# PIC32MZ2048EFM144 register map
Vendor: Microchip
Registers are 32-bit, read-write, reset 0x0 unless marked. A register's access mark holds for its fields unless they carry their own. Addresses are absolute, and some are shared; only a register's first bit layout is shown; [hi:lo] are bit positions; {n}, {i} and the like mark numbered series.

## INT
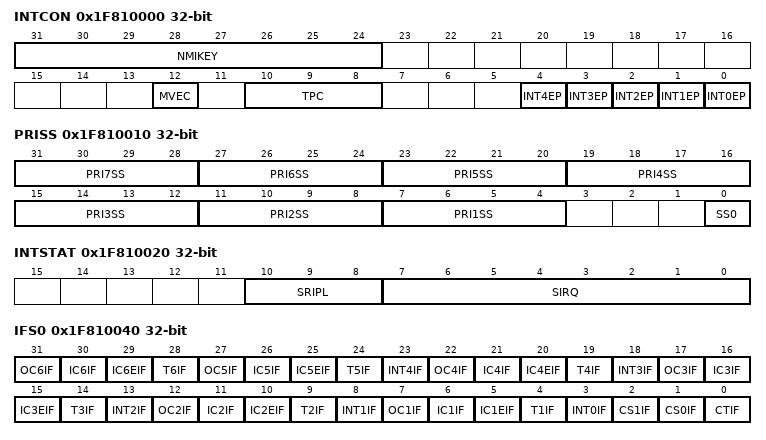
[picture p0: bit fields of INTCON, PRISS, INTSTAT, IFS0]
0x1F810000 INTCON reset not defined — (power-on value xxxxxxxx---------x-0-000---00000)
  [31:24] NMIKEY wo, [12] MVEC, [10:8] TPC, [n] INT{n}EP (n=0..4)
0x1F810010 PRISS
  [4n+3:4n] PRI{n}SS (n=1..7), [0] SS0
0x1F810020 INTSTAT ro
  [10:8] SRIPL, [7:0] SIRQ
0x1F810030 IPTMR
0x1F810040 IFS0
  [31] OC6IF, [30] IC6IF, [29] IC6EIF, [28] T6IF, [5n+2] OC{n}IF (n=1..5), [5n+1] IC{n}IF (n=1..5), [5n] IC{n}EIF (n=1..5), [5n-1] T{n}IF (n=1..5), [5n+3] INT{n}IF (n=0..4), [2] CS1IF, [1] CS0IF, [0] CTIF
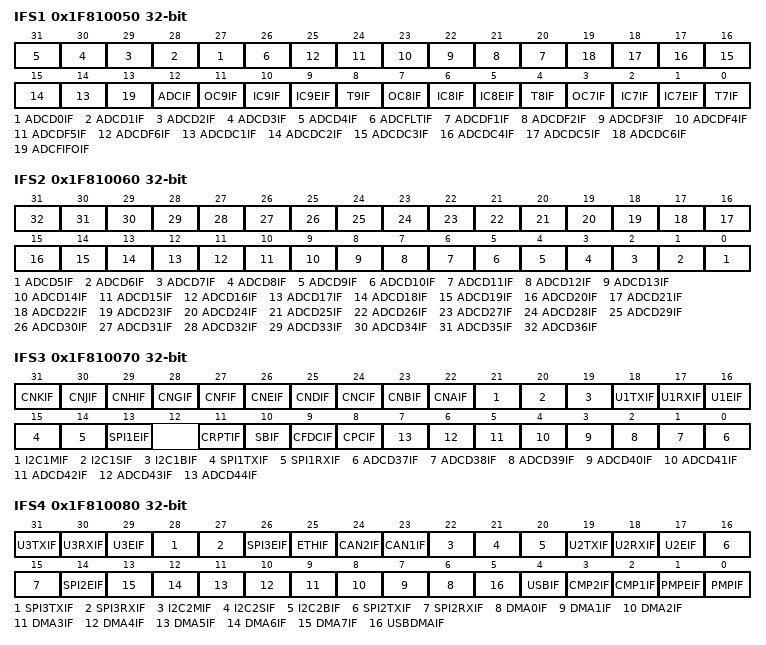
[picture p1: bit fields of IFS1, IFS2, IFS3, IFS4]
0x1F810050 IFS1
  [n+27] ADCD{n}IF (n=0..4), [26] ADCFLTIF, [n+19] ADCDF{n}IF (n=1..6), [n+13] ADCDC{n}IF (n=1..6), [13] ADCFIFOIF, [12] ADCIF, [11] OC9IF, [10] IC9IF, [9] IC9EIF, [8] T9IF, [7] OC8IF, [6] IC8IF, [5] IC8EIF, [4] T8IF, [3] OC7IF, [2] IC7IF, [1] IC7EIF, [0] T7IF
0x1F810060 IFS2
  [n-5] ADCD{n}IF (n=5..36)
0x1F810070 IFS3
  [31] CNKIF, [30] CNJIF, [29] CNHIF, [28] CNGIF, [27] CNFIF, [26] CNEIF, [25] CNDIF, [24] CNCIF, [23] CNBIF, [22] CNAIF, [21] I2C1MIF, [20] I2C1SIF, [19] I2C1BIF, [18] U1TXIF, [17] U1RXIF, [16] U1EIF, [15] SPI1TXIF, [14] SPI1RXIF, [13] SPI1EIF, [11] CRPTIF, [10] SBIF, [9] CFDCIF, [8] CPCIF, [n-37] ADCD{n}IF (n=37..44)
0x1F810080 IFS4
  [31] U3TXIF, [30] U3RXIF, [29] U3EIF, [28] SPI3TXIF, [27] SPI3RXIF, [26] SPI3EIF, [25] ETHIF, [24] CAN2IF, [23] CAN1IF, [22] I2C2MIF, [21] I2C2SIF, [20] I2C2BIF, [19] U2TXIF, [18] U2RXIF, [17] U2EIF, [16] SPI2TXIF, [15] SPI2RXIF, [14] SPI2EIF, [n+6] DMA{n}IF (n=0..7), [5] USBDMAIF, [4] USBIF, [3] CMP2IF, [2] CMP1IF, [1] PMPEIF, [0] PMPIF
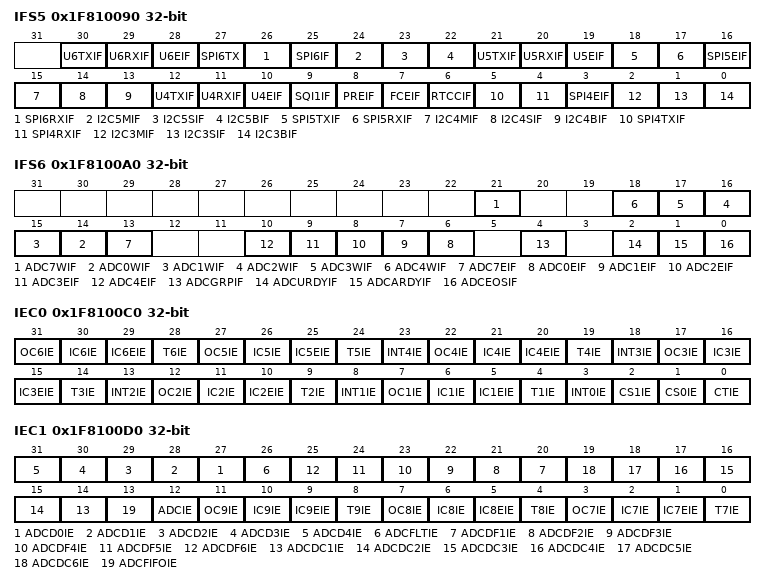
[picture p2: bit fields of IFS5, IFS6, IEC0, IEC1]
0x1F810090 IFS5
  [30] U6TXIF, [29] U6RXIF, [28] U6EIF, [27] SPI6TX, [26] SPI6RXIF, [25] SPI6IF, [24] I2C5MIF, [23] I2C5SIF, [22] I2C5BIF, [21] U5TXIF, [20] U5RXIF, [19] U5EIF, [18] SPI5TXIF, [17] SPI5RXIF, [16] SPI5EIF, [15] I2C4MIF, [14] I2C4SIF, [13] I2C4BIF, [12] U4TXIF, [11] U4RXIF, [10] U4EIF, [9] SQI1IF, [8] PREIF, [7] FCEIF, [6] RTCCIF, [5] SPI4TXIF, [4] SPI4RXIF, [3] SPI4EIF, [2] I2C3MIF, [1] I2C3SIF, [0] I2C3BIF
0x1F8100A0 IFS6
  [21] ADC7WIF, [n+14] ADC{n}WIF (n=0..4), [13] ADC7EIF, [n+6] ADC{n}EIF (n=0..4), [4] ADCGRPIF, [2] ADCURDYIF, [1] ADCARDYIF, [0] ADCEOSIF
0x1F8100C0 IEC0
  [31] OC6IE, [30] IC6IE, [29] IC6EIE, [28] T6IE, [5n+2] OC{n}IE (n=1..5), [5n+1] IC{n}IE (n=1..5), [5n] IC{n}EIE (n=1..5), [5n-1] T{n}IE (n=1..5), [5n+3] INT{n}IE (n=0..4), [2] CS1IE, [1] CS0IE, [0] CTIE
0x1F8100D0 IEC1 reset not defined — (power-on value 00000x00000000000000000000000000)
  [n+27] ADCD{n}IE (n=0..4), [26] ADCFLTIE, [n+19] ADCDF{n}IE (n=1..6), [n+13] ADCDC{n}IE (n=1..6), [13] ADCFIFOIE, [12] ADCIE, [11] OC9IE, [10] IC9IE, [9] IC9EIE, [8] T9IE, [7] OC8IE, [6] IC8IE, [5] IC8EIE, [4] T8IE, [3] OC7IE, [2] IC7IE, [1] IC7EIE, [0] T7IE
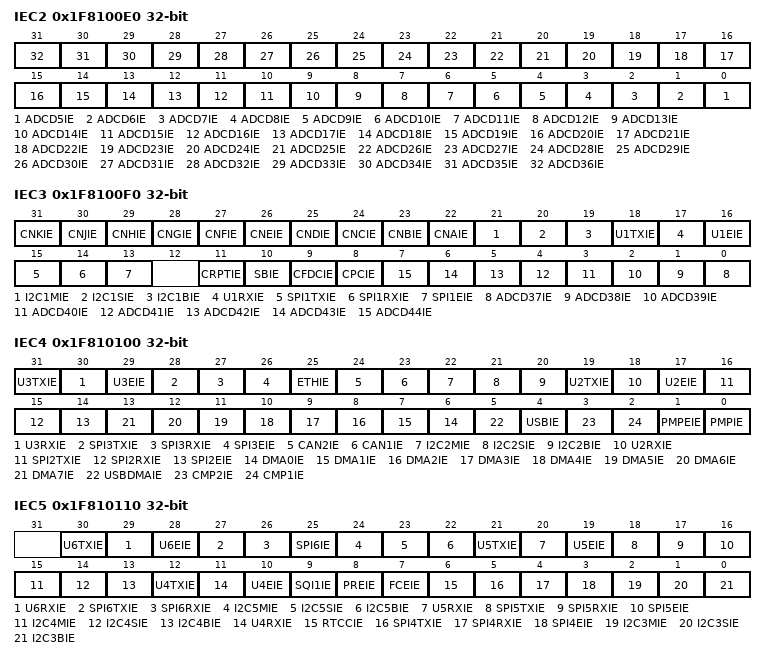
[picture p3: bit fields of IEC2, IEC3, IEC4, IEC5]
0x1F8100E0 IEC2
  [n-5] ADCD{n}IE (n=5..36)
0x1F8100F0 IEC3
  [31] CNKIE, [30] CNJIE, [29] CNHIE, [28] CNGIE, [27] CNFIE, [26] CNEIE, [25] CNDIE, [24] CNCIE, [23] CNBIE, [22] CNAIE, [21] I2C1MIE, [20] I2C1SIE, [19] I2C1BIE, [18] U1TXIE, [17] U1RXIE, [16] U1EIE, [15] SPI1TXIE, [14] SPI1RXIE, [13] SPI1EIE, [11] CRPTIE, [10] SBIE, [9] CFDCIE, [8] CPCIE, [n-37] ADCD{n}IE (n=37..44)
0x1F810100 IEC4
  [31] U3TXIE, [30] U3RXIE, [29] U3EIE, [28] SPI3TXIE, [27] SPI3RXIE, [26] SPI3EIE, [25] ETHIE, [24] CAN2IE, [23] CAN1IE, [22] I2C2MIE, [21] I2C2SIE, [20] I2C2BIE, [19] U2TXIE, [18] U2RXIE, [17] U2EIE, [16] SPI2TXIE, [15] SPI2RXIE, [14] SPI2EIE, [n+6] DMA{n}IE (n=0..7), [5] USBDMAIE, [4] USBIE, [3] CMP2IE, [2] CMP1IE, [1] PMPEIE, [0] PMPIE
0x1F810110 IEC5
  [30] U6TXIE, [29] U6RXIE, [28] U6EIE, [27] SPI6TXIE, [26] SPI6RXIE, [25] SPI6IE, [24] I2C5MIE, [23] I2C5SIE, [22] I2C5BIE, [21] U5TXIE, [20] U5RXIE, [19] U5EIE, [18] SPI5TXIE, [17] SPI5RXIE, [16] SPI5EIE, [15] I2C4MIE, [14] I2C4SIE, [13] I2C4BIE, [12] U4TXIE, [11] U4RXIE, [10] U4EIE, [9] SQI1IE, [8] PREIE, [7] FCEIE, [6] RTCCIE, [5] SPI4TXIE, [4] SPI4RXIE, [3] SPI4EIE, [2] I2C3MIE, [1] I2C3SIE, [0] I2C3BIE
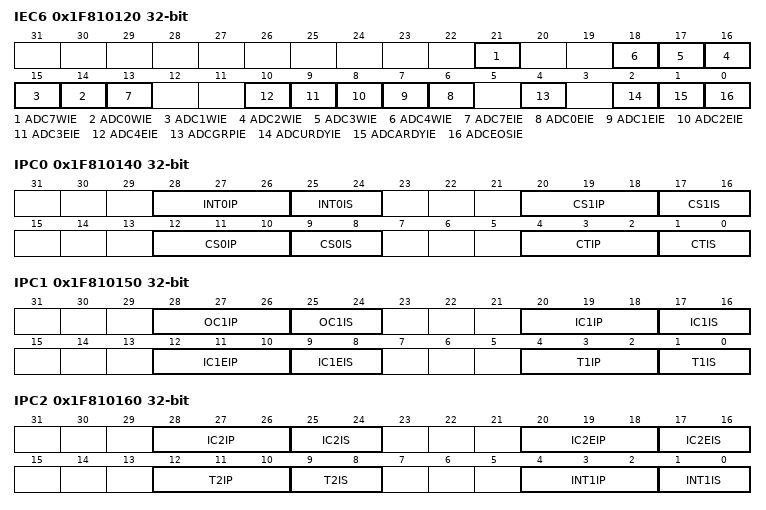
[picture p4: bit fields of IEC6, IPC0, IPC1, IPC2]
0x1F810120 IEC6
  [21] ADC7WIE, [n+14] ADC{n}WIE (n=0..4), [13] ADC7EIE, [n+6] ADC{n}EIE (n=0..4), [4] ADCGRPIE, [2] ADCURDYIE, [1] ADCARDYIE, [0] ADCEOSIE
0x1F810140 IPC0
  [28:26] INT0IP, [25:24] INT0IS, [20:18] CS1IP, [17:16] CS1IS, [12:10] CS0IP, [9:8] CS0IS, [4:2] CTIP, [1:0] CTIS
0x1F810150 IPC1
  [28:26] OC1IP, [25:24] OC1IS, [20:18] IC1IP, [17:16] IC1IS, [12:10] IC1EIP, [9:8] IC1EIS, [4:2] T1IP, [1:0] T1IS
0x1F810160 IPC2
  [28:26] IC2IP, [25:24] IC2IS, [20:18] IC2EIP, [17:16] IC2EIS, [12:10] T2IP, [9:8] T2IS, [4:2] INT1IP, [1:0] INT1IS
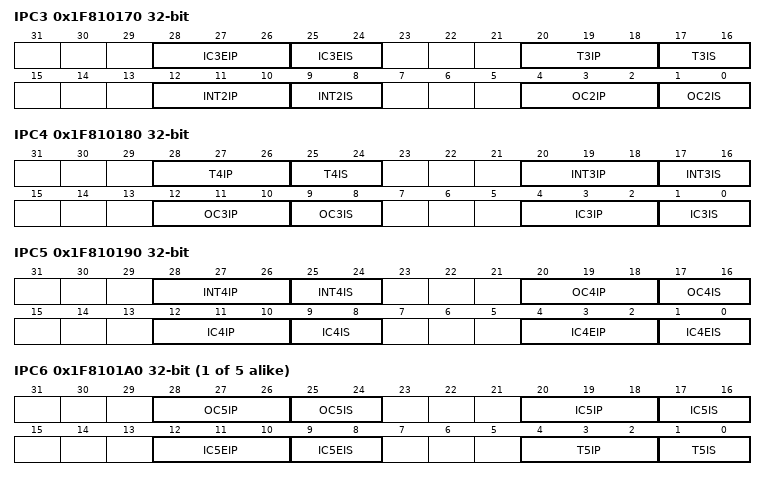
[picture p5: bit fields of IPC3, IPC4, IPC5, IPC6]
0x1F810170 IPC3
  [28:26] IC3EIP, [25:24] IC3EIS, [20:18] T3IP, [17:16] T3IS, [12:10] INT2IP, [9:8] INT2IS, [4:2] OC2IP, [1:0] OC2IS
0x1F810180 IPC4
  [28:26] T4IP, [25:24] T4IS, [20:18] INT3IP, [17:16] INT3IS, [12:10] OC3IP, [9:8] OC3IS, [4:2] IC3IP, [1:0] IC3IS
0x1F810190 IPC5
  [28:26] INT4IP, [25:24] INT4IS, [20:18] OC4IP, [17:16] OC4IS, [12:10] IC4IP, [9:8] IC4IS, [4:2] IC4EIP, [1:0] IC4EIS
{0x1F810140+0x10*i} IPC{i} (i=6..10)
  [28:26] OC{i-1}IP, [25:24] OC{i-1}IS, [20:18] IC{i-1}IP, [17:16] IC{i-1}IS, [12:10] IC{i-1}EIP, [9:8] IC{i-1}EIS, [4:2] T{i-1}IP, [1:0] T{i-1}IS
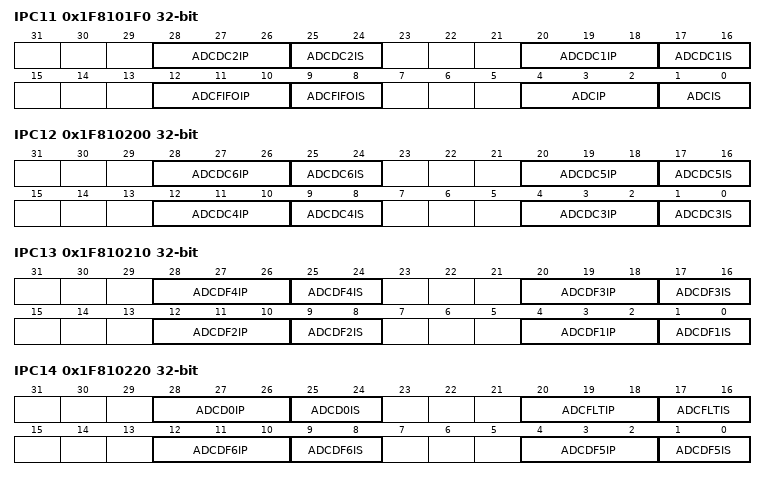
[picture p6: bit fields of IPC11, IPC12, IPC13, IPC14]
0x1F8101F0 IPC11
  [28:26] ADCDC2IP, [25:24] ADCDC2IS, [20:18] ADCDC1IP, [17:16] ADCDC1IS, [12:10] ADCFIFOIP, [9:8] ADCFIFOIS, [4:2] ADCIP, [1:0] ADCIS
0x1F810200 IPC12
  [8n-20:8n-22] ADCDC{n}IP (n=3..6), [8n-23:8n-24] ADCDC{n}IS (n=3..6)
0x1F810210 IPC13
  [8n-4:8n-6] ADCDF{n}IP (n=1..4), [8n-7:8n-8] ADCDF{n}IS (n=1..4)
0x1F810220 IPC14
  [28:26] ADCD0IP, [25:24] ADCD0IS, [20:18] ADCFLTIP, [17:16] ADCFLTIS, [12:10] ADCDF6IP, [9:8] ADCDF6IS, [4:2] ADCDF5IP, [1:0] ADCDF5IS
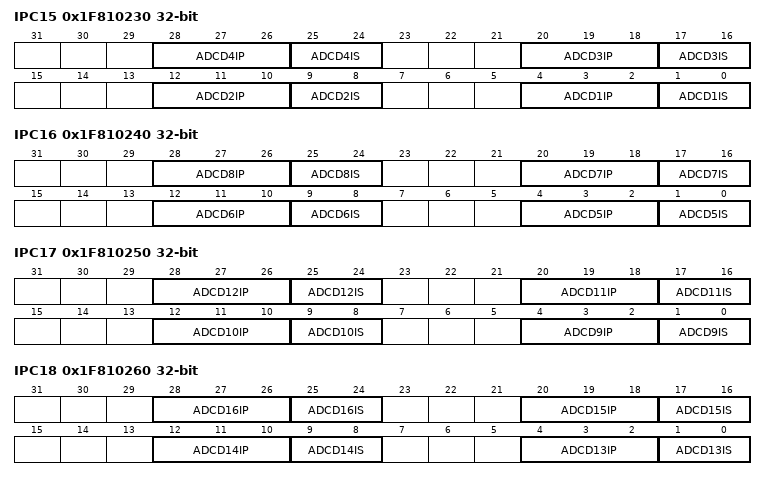
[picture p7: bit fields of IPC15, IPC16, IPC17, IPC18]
0x1F810230 IPC15
  [8n-4:8n-6] ADCD{n}IP (n=1..4), [8n-7:8n-8] ADCD{n}IS (n=1..4)
0x1F810240 IPC16
  [8n-36:8n-38] ADCD{n}IP (n=5..8), [8n-39:8n-40] ADCD{n}IS (n=5..8)
0x1F810250 IPC17
  [8n-68:8n-70] ADCD{n}IP (n=9..12), [8n-71:8n-72] ADCD{n}IS (n=9..12)
0x1F810260 IPC18
  [8n-100:8n-102] ADCD{n}IP (n=13..16), [8n-103:8n-104] ADCD{n}IS (n=13..16)
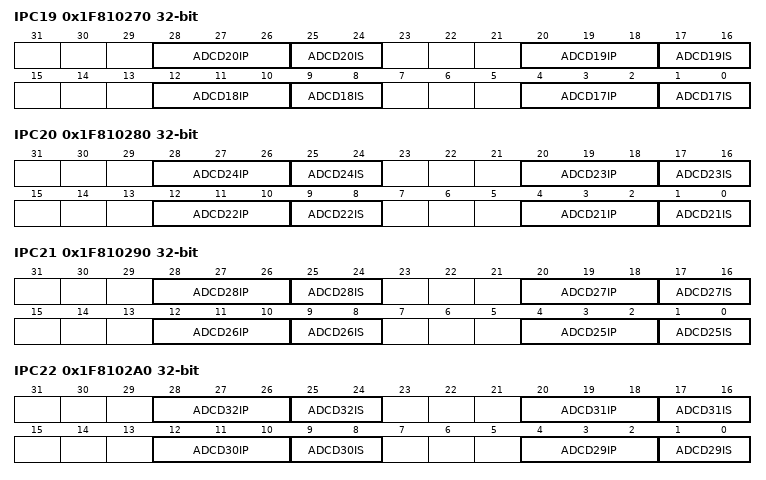
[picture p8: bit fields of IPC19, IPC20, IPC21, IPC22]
0x1F810270 IPC19
  [8n-132:8n-134] ADCD{n}IP (n=17..20), [8n-135:8n-136] ADCD{n}IS (n=17..20)
0x1F810280 IPC20
  [8n-164:8n-166] ADCD{n}IP (n=21..24), [8n-167:8n-168] ADCD{n}IS (n=21..24)
0x1F810290 IPC21
  [8n-196:8n-198] ADCD{n}IP (n=25..28), [8n-199:8n-200] ADCD{n}IS (n=25..28)
0x1F8102A0 IPC22
  [8n-228:8n-230] ADCD{n}IP (n=29..32), [8n-231:8n-232] ADCD{n}IS (n=29..32)
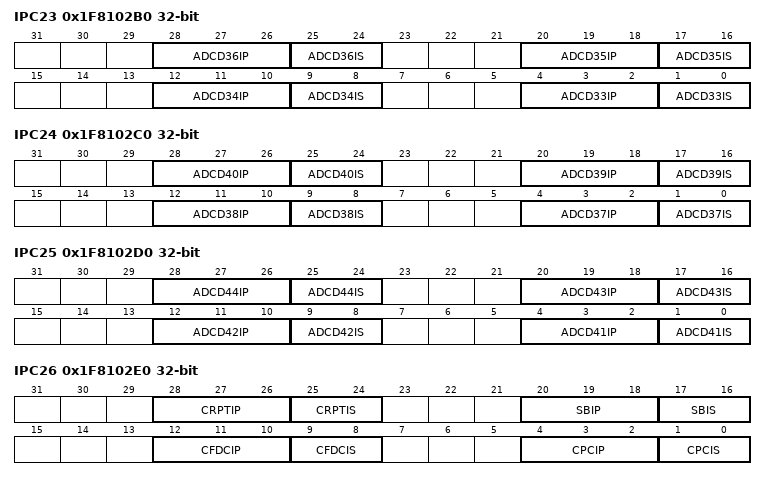
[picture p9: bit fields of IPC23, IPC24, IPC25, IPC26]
0x1F8102B0 IPC23
  [8n-260:8n-262] ADCD{n}IP (n=33..36), [8n-263:8n-264] ADCD{n}IS (n=33..36)
0x1F8102C0 IPC24
  [8n-292:8n-294] ADCD{n}IP (n=37..40), [8n-295:8n-296] ADCD{n}IS (n=37..40)
0x1F8102D0 IPC25
  [8n-324:8n-326] ADCD{n}IP (n=41..44), [8n-327:8n-328] ADCD{n}IS (n=41..44)
0x1F8102E0 IPC26
  [28:26] CRPTIP, [25:24] CRPTIS, [20:18] SBIP, [17:16] SBIS, [12:10] CFDCIP, [9:8] CFDCIS, [4:2] CPCIP, [1:0] CPCIS
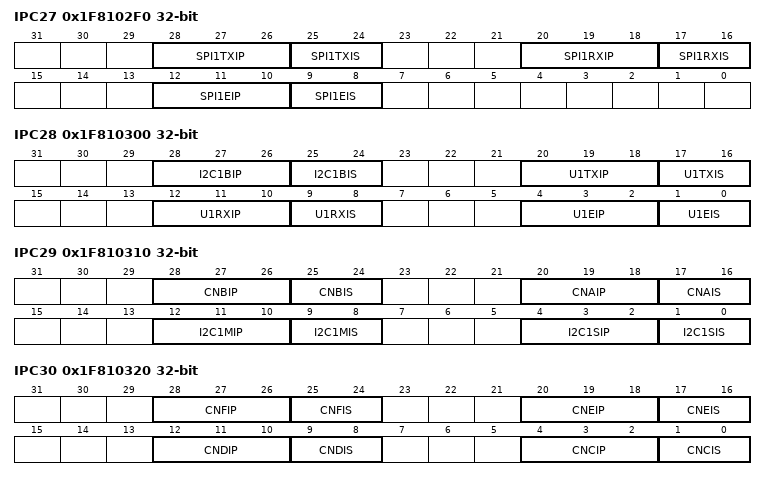
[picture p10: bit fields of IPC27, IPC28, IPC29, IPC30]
0x1F8102F0 IPC27
  [28:26] SPI1TXIP, [25:24] SPI1TXIS, [20:18] SPI1RXIP, [17:16] SPI1RXIS, [12:10] SPI1EIP, [9:8] SPI1EIS
0x1F810300 IPC28
  [28:26] I2C1BIP, [25:24] I2C1BIS, [20:18] U1TXIP, [17:16] U1TXIS, [12:10] U1RXIP, [9:8] U1RXIS, [4:2] U1EIP, [1:0] U1EIS
0x1F810310 IPC29
  [28:26] CNBIP, [25:24] CNBIS, [20:18] CNAIP, [17:16] CNAIS, [12:10] I2C1MIP, [9:8] I2C1MIS, [4:2] I2C1SIP, [1:0] I2C1SIS
0x1F810320 IPC30
  [28:26] CNFIP, [25:24] CNFIS, [20:18] CNEIP, [17:16] CNEIS, [12:10] CNDIP, [9:8] CNDIS, [4:2] CNCIP, [1:0] CNCIS
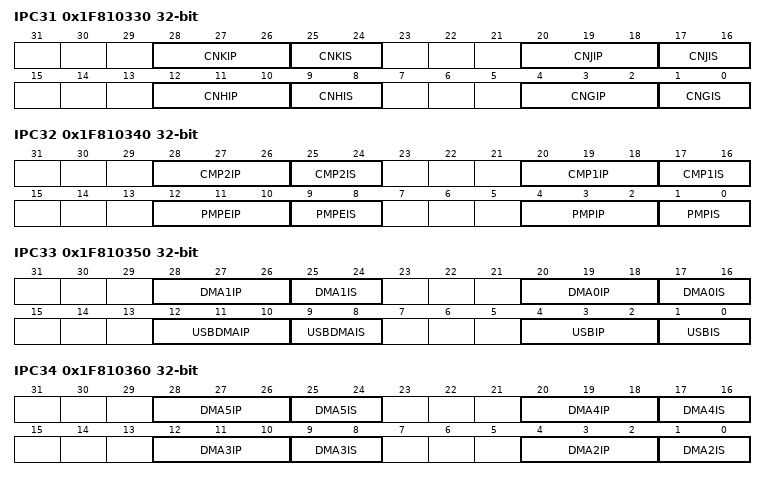
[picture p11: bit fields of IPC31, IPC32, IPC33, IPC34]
0x1F810330 IPC31
  [28:26] CNKIP, [25:24] CNKIS, [20:18] CNJIP, [17:16] CNJIS, [12:10] CNHIP, [9:8] CNHIS, [4:2] CNGIP, [1:0] CNGIS
0x1F810340 IPC32
  [28:26] CMP2IP, [25:24] CMP2IS, [20:18] CMP1IP, [17:16] CMP1IS, [12:10] PMPEIP, [9:8] PMPEIS, [4:2] PMPIP, [1:0] PMPIS
0x1F810350 IPC33
  [28:26] DMA1IP, [25:24] DMA1IS, [20:18] DMA0IP, [17:16] DMA0IS, [12:10] USBDMAIP, [9:8] USBDMAIS, [4:2] USBIP, [1:0] USBIS
0x1F810360 IPC34
  [8n-12:8n-14] DMA{n}IP (n=2..5), [8n-15:8n-16] DMA{n}IS (n=2..5)
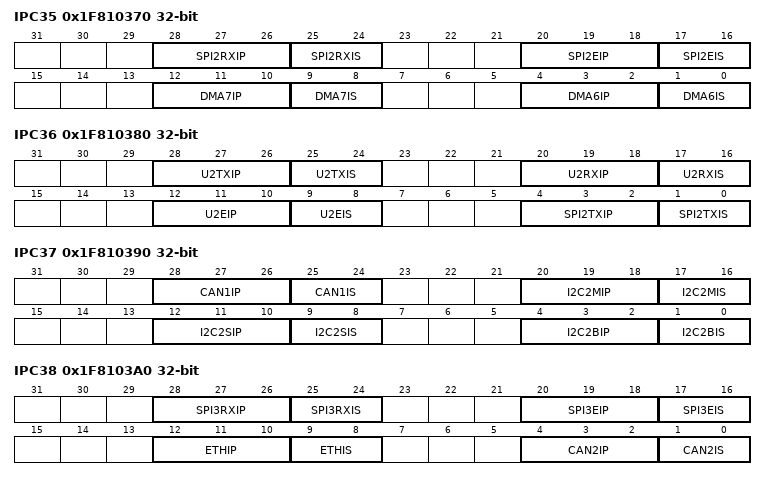
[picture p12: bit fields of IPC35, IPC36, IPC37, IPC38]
0x1F810370 IPC35
  [28:26] SPI2RXIP, [25:24] SPI2RXIS, [20:18] SPI2EIP, [17:16] SPI2EIS, [12:10] DMA7IP, [9:8] DMA7IS, [4:2] DMA6IP, [1:0] DMA6IS
0x1F810380 IPC36
  [28:26] U2TXIP, [25:24] U2TXIS, [20:18] U2RXIP, [17:16] U2RXIS, [12:10] U2EIP, [9:8] U2EIS, [4:2] SPI2TXIP, [1:0] SPI2TXIS
0x1F810390 IPC37
  [28:26] CAN1IP, [25:24] CAN1IS, [20:18] I2C2MIP, [17:16] I2C2MIS, [12:10] I2C2SIP, [9:8] I2C2SIS, [4:2] I2C2BIP, [1:0] I2C2BIS
0x1F8103A0 IPC38
  [28:26] SPI3RXIP, [25:24] SPI3RXIS, [20:18] SPI3EIP, [17:16] SPI3EIS, [12:10] ETHIP, [9:8] ETHIS, [4:2] CAN2IP, [1:0] CAN2IS
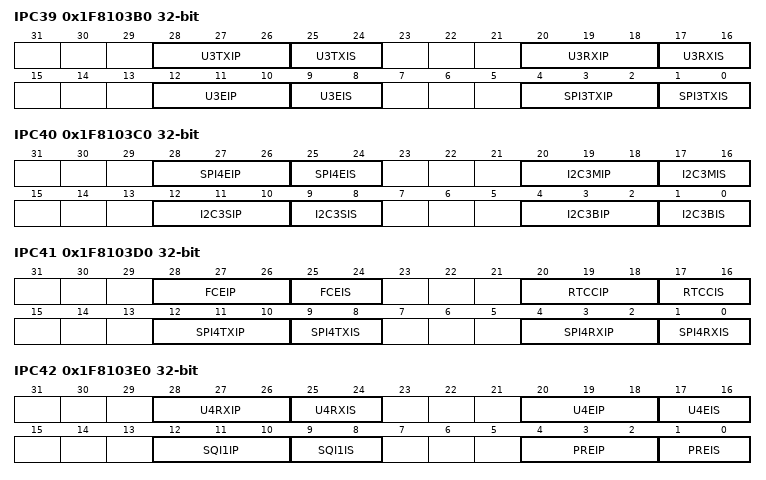
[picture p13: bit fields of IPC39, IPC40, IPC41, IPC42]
0x1F8103B0 IPC39
  [28:26] U3TXIP, [25:24] U3TXIS, [20:18] U3RXIP, [17:16] U3RXIS, [12:10] U3EIP, [9:8] U3EIS, [4:2] SPI3TXIP, [1:0] SPI3TXIS
0x1F8103C0 IPC40
  [28:26] SPI4EIP, [25:24] SPI4EIS, [20:18] I2C3MIP, [17:16] I2C3MIS, [12:10] I2C3SIP, [9:8] I2C3SIS, [4:2] I2C3BIP, [1:0] I2C3BIS
0x1F8103D0 IPC41
  [28:26] FCEIP, [25:24] FCEIS, [20:18] RTCCIP, [17:16] RTCCIS, [12:10] SPI4TXIP, [9:8] SPI4TXIS, [4:2] SPI4RXIP, [1:0] SPI4RXIS
0x1F8103E0 IPC42
  [28:26] U4RXIP, [25:24] U4RXIS, [20:18] U4EIP, [17:16] U4EIS, [12:10] SQI1IP, [9:8] SQI1IS, [4:2] PREIP, [1:0] PREIS
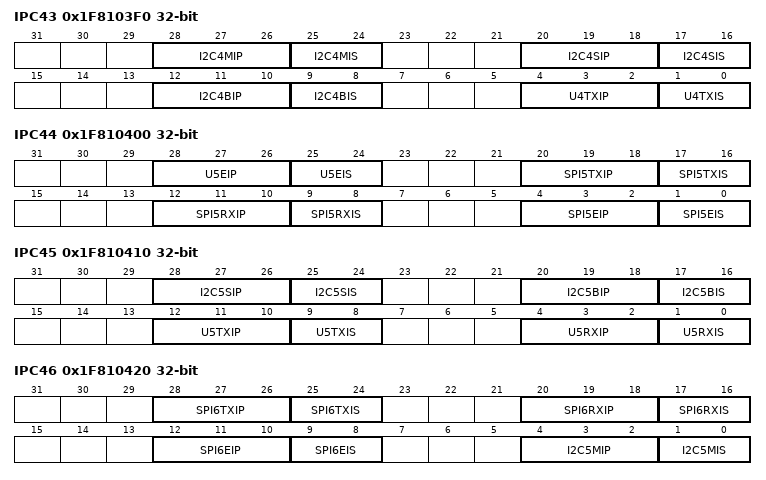
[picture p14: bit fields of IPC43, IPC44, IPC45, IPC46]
0x1F8103F0 IPC43
  [28:26] I2C4MIP, [25:24] I2C4MIS, [20:18] I2C4SIP, [17:16] I2C4SIS, [12:10] I2C4BIP, [9:8] I2C4BIS, [4:2] U4TXIP, [1:0] U4TXIS
0x1F810400 IPC44
  [28:26] U5EIP, [25:24] U5EIS, [20:18] SPI5TXIP, [17:16] SPI5TXIS, [12:10] SPI5RXIP, [9:8] SPI5RXIS, [4:2] SPI5EIP, [1:0] SPI5EIS
0x1F810410 IPC45
  [28:26] I2C5SIP, [25:24] I2C5SIS, [20:18] I2C5BIP, [17:16] I2C5BIS, [12:10] U5TXIP, [9:8] U5TXIS, [4:2] U5RXIP, [1:0] U5RXIS
0x1F810420 IPC46
  [28:26] SPI6TXIP, [25:24] SPI6TXIS, [20:18] SPI6RXIP, [17:16] SPI6RXIS, [12:10] SPI6EIP, [9:8] SPI6EIS, [4:2] I2C5MIP, [1:0] I2C5MIS
0x1F810430 IPC47
  [20:18] U6TXIP, [17:16] U6TXIS, [12:10] U6RXIP, [9:8] U6RXIS, [4:2] U6EIP, [1:0] U6EIS
0x1F810440 IPC48
  [20:18] ADCURDYIP, [17:16] ADCURDYIS, [12:10] ADCARDYIP, [9:8] ADCARDYIS, [4:2] ADCEOSIP, [1:0] ADCEOSIS
0x1F810450 IPC49
  [28:26] ADC1EIP, [25:24] ADC1EIS, [20:18] ADC0EIP, [17:16] ADC0EIS, [4:2] ADCGRPIP, [1:0] ADCGRPIS
0x1F810460 IPC50
  [20:18] ADC4EIP, [17:16] ADC4EIS, [12:10] ADC3EIP, [9:8] ADC3EIS, [4:2] ADC2EIP, [1:0] ADC2EIS
0x1F810470 IPC51
  [28:26] ADC1WIP, [25:24] ADC1WIS, [20:18] ADC0WIP, [17:16] ADC0WIS, [12:10] ADC7EIP, [9:8] ADC7EIS
0x1F810480 IPC52
  [20:18] ADC4WIP, [17:16] ADC4WIS, [12:10] ADC3WIP, [9:8] ADC3WIS, [4:2] ADC2WIP, [1:0] ADC2WIS
0x1F810490 IPC53
  [12:10] ADC7WIP, [9:8] ADC7WIS
{0x1F810540+4i} OFF{i:03} (i=0..44)
  [17:1] VOFF
0x1F8105F4 OFF045 reset not defined — (power-on value --------------xxxxxxxxxxxxxxxxx-)
  [17:1] VOFF
{0x1F810540+4i} OFF{i:03} (i=46..57)
  [17:1] VOFF
0x1F810628 OFF058 reset not defined — (power-on value --------------xxxxxxxxxxxxxxxxx-)
  [17:1] VOFF
{0x1F810540+4i} OFF{i:03} (i=59..107)
  [17:1] VOFF
{0x1F810540+4i} OFF{i} (i=109..190)
  [17:1] VOFF
{0x1F810540+4i} OFF{i} (i=192..194)
  [17:1] VOFF
0x1F810850 OFF196
  [17:1] VOFF
{0x1F810540+4i} OFF{i} (i=198..202)
  [17:1] VOFF
{0x1F810540+4i} OFF{i} (i=205..210)
  [17:1] VOFF
0x1F810894 OFF213
  [17:1] VOFF
0x1F811000 DMACON
  [15] ON, [12] SUSPEND, [11] DMABUSY
0x1F811010 DMASTAT ro
  [31] RDWR, [2:0] DMACH
0x1F811020 DMAADDR ro
0x1F811030 DCRCCON
  [29:28] BYTO, [27] WBO, [24] BITO, [12:8] PLEN, [7] CRCEN, [6] CRCAPP, [5] CRCTYP, [2:0] CRCCH
0x1F811040 DCRCDATA
0x1F811050 DCRCXOR
